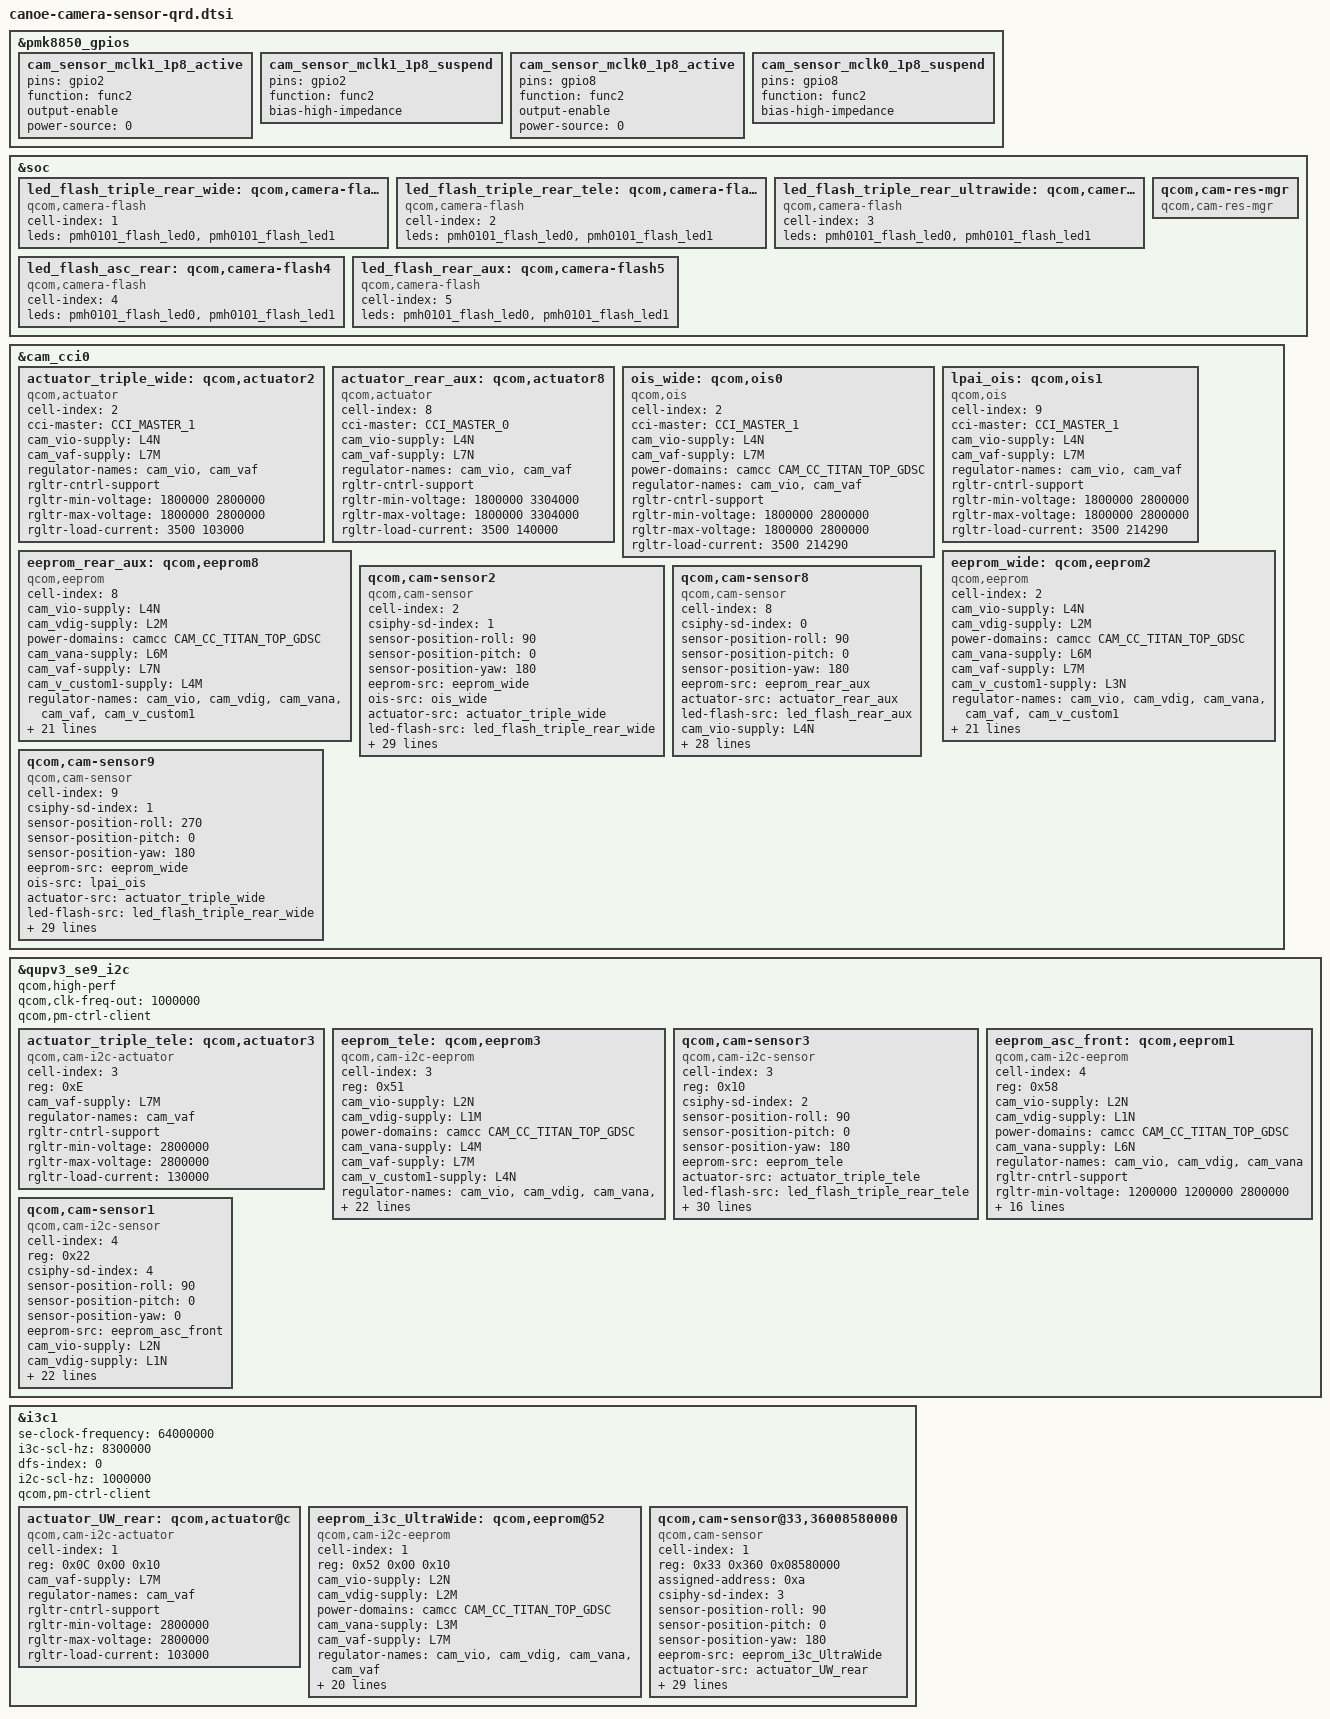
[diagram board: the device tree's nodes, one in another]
// SPDX-License-Identifier: BSD-3-Clause
/*
 * Copyright (c) 2024 Qualcomm Innovation Center, Inc. All rights reserved.
 */

#include <dt-bindings/msm-camera.h>

&pmk8850_gpios {
	cam_sensor_mclk1_1p8_active: cam_sensor_mclk1_1p8_active {
			pins = "gpio2";
			function = "func2";
			output-enable;
			power-source = <0>; /* 1.8 V */
	};

	cam_sensor_mclk1_1p8_suspend: cam_sensor_mclk1_1p8_suspend {
			pins = "gpio2";
			function = "func2";
			bias-high-impedance;
	};

	cam_sensor_mclk0_1p8_active: cam_sensor_mclk0_1p8_active {
			pins = "gpio8";
			function = "func2";
			output-enable;
			power-source = <0>; /* 1.8 V */
	};

	cam_sensor_mclk0_1p8_suspend: cam_sensor_mclk0_1p8_suspend {
			pins = "gpio8";
			function = "func2";
			bias-high-impedance;
	};
};

&soc {
	led_flash_triple_rear_wide: qcom,camera-flash1 {
		cell-index = <1>;
		compatible = "qcom,camera-flash";
		leds = <&pmh0101_flash_led0 &pmh0101_flash_led1>;
		status = "ok";
	};

	led_flash_triple_rear_tele: qcom,camera-flash2 {
		cell-index = <2>;
		compatible = "qcom,camera-flash";
		leds = <&pmh0101_flash_led0 &pmh0101_flash_led1>;
		status = "ok";
	};

	led_flash_triple_rear_ultrawide: qcom,camera-flash3 {
		cell-index = <3>;
		compatible = "qcom,camera-flash";
		leds = <&pmh0101_flash_led0 &pmh0101_flash_led1>;
		status = "ok";
	};

	led_flash_asc_rear: qcom,camera-flash4 {
		cell-index = <4>;
		compatible = "qcom,camera-flash";
		leds = <&pmh0101_flash_led0 &pmh0101_flash_led1>;
		status = "ok";
	};

	led_flash_rear_aux: qcom,camera-flash5 {
		cell-index = <5>;
		compatible = "qcom,camera-flash";
		leds = <&pmh0101_flash_led0 &pmh0101_flash_led1>;
		status = "ok";
	};

	qcom,cam-res-mgr {
		compatible = "qcom,cam-res-mgr";
		status = "ok";
	};
};

&cam_cci0 {

	actuator_triple_wide: qcom,actuator2 {
		cell-index = <2>;
		compatible = "qcom,actuator";
		cci-master = <CCI_MASTER_1>;
		cam_vio-supply = <&L4N>;
		cam_vaf-supply = <&L7M>;
		regulator-names = "cam_vio","cam_vaf";
		rgltr-cntrl-support;
		rgltr-min-voltage = <1800000 2800000>;
		rgltr-max-voltage = <1800000 2800000>;
		rgltr-load-current = <3500 103000>;
		status = "ok";
	};

	actuator_rear_aux: qcom,actuator8 {
		cell-index = <8>;
		compatible = "qcom,actuator";
		cci-master = <CCI_MASTER_0>;
		cam_vio-supply = <&L4N>;
		cam_vaf-supply = <&L7N>;
		regulator-names = "cam_vio","cam_vaf";
		rgltr-cntrl-support;
		rgltr-min-voltage = <1800000 3304000>;
		rgltr-max-voltage = <1800000 3304000>;
		rgltr-load-current = <3500 140000>;
		status = "ok";
	};

	ois_wide: qcom,ois0 {
		cell-index = <2>;
		compatible = "qcom,ois";
		cci-master = <CCI_MASTER_1>;
		cam_vio-supply = <&L4N>;
		cam_vaf-supply = <&L7M>;
		power-domains = <&camcc CAM_CC_TITAN_TOP_GDSC>;
		regulator-names = "cam_vio","cam_vaf";
		rgltr-cntrl-support;
		rgltr-min-voltage = <1800000 2800000>;
		rgltr-max-voltage = <1800000 2800000>;
		rgltr-load-current = <3500 214290>;
		status = "ok";
	};

	lpai_ois: qcom,ois1 {
		cell-index = <9>;
		compatible = "qcom,ois";
		cci-master = <CCI_MASTER_1>;
		cam_vio-supply = <&L4N>;
		cam_vaf-supply = <&L7M>;
		regulator-names = "cam_vio","cam_vaf";
		rgltr-cntrl-support;
		rgltr-min-voltage = <1800000 2800000>;
		rgltr-max-voltage = <1800000 2800000>;
		rgltr-load-current = <3500 214290>;
		status = "ok";
	};

	eeprom_rear_aux: qcom,eeprom8 {
		cell-index = <8>;
		compatible = "qcom,eeprom";
		cam_vio-supply = <&L4N>;
		cam_vdig-supply = <&L2M>;
		power-domains = <&camcc CAM_CC_TITAN_TOP_GDSC>;
		cam_vana-supply = <&L6M>;
		cam_vaf-supply = <&L7N>;
		cam_v_custom1-supply = <&L4M>;
		regulator-names = "cam_vio", "cam_vdig", "cam_vana",
			"cam_vaf", "cam_v_custom1";
		rgltr-cntrl-support;
		rgltr-min-voltage = <1800000 1100000 2800000 3304000 2200000>;
		rgltr-max-voltage = <1800000 1100000 2800000 3304000 2200000>;
		rgltr-load-current = <4280 1050000 114500 140000 127100>;
		gpio-no-mux = <0>;
		pinctrl-names = "cam_default", "cam_suspend";
		pinctrl-0 = <&cam_sensor_mclk0_1p8_active
				 &cam_sensor_1p8_rst0_active>;
		pinctrl-1 = <&cam_sensor_mclk0_1p8_suspend
				 &cam_sensor_1p8_rst0_suspend>;
		gpios = <&pmh0101_gpios 4 0>;
		gpio-reset = <0>;
		gpio-req-tbl-num = <0>;
		gpio-req-tbl-flags = <0>;
		gpio-req-tbl-label = "CAM_RESET0_1P8";
		cci-master = <CCI_MASTER_0>;
		clocks = <&rpmhcc RPMH_DIV_CLK1>;
		clock-names = "cam_clk";
		clock-cntl-level = "nominal";
		clock-rates = <24000000>;
		status = "ok";
	};

	eeprom_wide: qcom,eeprom2 {
		cell-index = <2>;
		compatible = "qcom,eeprom";
		cam_vio-supply = <&L4N>;
		cam_vdig-supply = <&L2M>;
		power-domains = <&camcc CAM_CC_TITAN_TOP_GDSC>;
		cam_vana-supply = <&L6M>;
		cam_vaf-supply = <&L7M>;
		cam_v_custom1-supply = <&L3N>;
		regulator-names = "cam_vio", "cam_vdig", "cam_vana",
			"cam_vaf", "cam_v_custom1";
		rgltr-cntrl-support;
		rgltr-min-voltage = <1800000 1100000 2800000 2800000 1800000>;
		rgltr-max-voltage = <1800000 1100000 2800000 2800000 1800000>;
		rgltr-load-current = <3500 913200 91430 103000 63100>;
		gpio-no-mux = <0>;
		pinctrl-names = "cam_default", "cam_suspend";
		pinctrl-0 = <&cam_sensor_mclk1_1p8_active
				&cam_sensor_active_rst1>;
		pinctrl-1 = <&cam_sensor_mclk1_1p8_suspend
				&cam_sensor_suspend_rst1>;
		gpios = <&tlmm 15 0>;
		gpio-reset = <0>;
		gpio-req-tbl-num = <0>;
		gpio-req-tbl-flags = <0>;
		gpio-req-tbl-label = "CAM_RESET1";
		cci-master = <CCI_MASTER_1>;
		clocks = <&rpmhcc RPMH_DIV_CLK1>;
		clock-names = "cam_clk";
		clock-cntl-level = "nominal";
		clock-rates = <24000000>;
		status = "ok";
	};

	qcom,cam-sensor2 {
		cell-index = <2>;
		compatible = "qcom,cam-sensor";
		csiphy-sd-index = <1>;
		sensor-position-roll = <90>;
		sensor-position-pitch = <0>;
		sensor-position-yaw = <180>;
		eeprom-src = <&eeprom_wide>;
		ois-src = <&ois_wide>;
		actuator-src = <&actuator_triple_wide>;
		led-flash-src = <&led_flash_triple_rear_wide>;
		cam_vio-supply = <&L4N>;
		cam_vdig-supply = <&L2M>;
		power-domains = <&camcc CAM_CC_TITAN_TOP_GDSC>;
		cam_vana-supply = <&L6M>;
		cam_vaf-supply = <&L7M>;
		cam_v_custom1-supply = <&L3N>;
		regulator-names = "cam_vio", "cam_vdig","cam_vana",
			"cam_vaf", "cam_v_custom1";
		rgltr-cntrl-support;
		rgltr-min-voltage = <1800000 1100000 2800000 2800000 1800000>;
		rgltr-max-voltage = <1800000 1100000 2800000 2800000 1800000>;
		rgltr-load-current = <3500 913200 91430 103000 63100>;
		gpio-no-mux = <0>;
		pinctrl-names = "cam_default", "cam_suspend";
		pinctrl-0 = <&cam_sensor_mclk1_1p8_active
				 &cam_sensor_active_rst1>;
		pinctrl-1 = <&cam_sensor_mclk1_1p8_suspend
				 &cam_sensor_suspend_rst1>;
		gpios = <&tlmm 15 0>;
		gpio-reset = <0>;
		gpio-req-tbl-num = <0>;
		gpio-req-tbl-flags = <0>;
		gpio-req-tbl-label = "CAM_RESET1";
		cci-master = <CCI_MASTER_1>;
		clocks = <&rpmhcc RPMH_DIV_CLK1>;
		clock-names = "cam_clk";
		clock-cntl-level = "nominal";
		clock-rates = <24000000>;
		status = "ok";
	};

	qcom,cam-sensor8 {
		cell-index = <8>;
		compatible = "qcom,cam-sensor";
		csiphy-sd-index = <0>;
		sensor-position-roll = <90>;
		sensor-position-pitch = <0>;
		sensor-position-yaw = <180>;
		eeprom-src = <&eeprom_rear_aux>;
		actuator-src = <&actuator_rear_aux>;
		led-flash-src = <&led_flash_rear_aux>;
		cam_vio-supply = <&L4N>;
		cam_vdig-supply = <&L2M>;
		power-domains = <&camcc CAM_CC_TITAN_TOP_GDSC>;
		cam_vana-supply = <&L6M>;
		cam_vaf-supply = <&L7N>;
		cam_v_custom1-supply = <&L4M>;
		regulator-names = "cam_vio", "cam_vdig", "cam_vana",
			"cam_vaf", "cam_v_custom1";
		rgltr-cntrl-support;
		rgltr-min-voltage = <1800000 1100000 2800000 3304000 2200000>;
		rgltr-max-voltage = <1800000 1100000 2800000 3304000 2200000>;
		rgltr-load-current = <4280 1050000 114500 140000 127100>;
		gpio-no-mux = <0>;
		pinctrl-names = "cam_default", "cam_suspend";
		pinctrl-0 = <&cam_sensor_mclk0_1p8_active
				 &cam_sensor_1p8_rst0_active>;
		pinctrl-1 = <&cam_sensor_mclk0_1p8_suspend
				 &cam_sensor_1p8_rst0_suspend>;
		gpios = <&pmh0101_gpios 4 0>;
		gpio-reset = <0>;
		gpio-req-tbl-num = <0>;
		gpio-req-tbl-flags = <0>;
		gpio-req-tbl-label = "CAM_RESET0_1P8";
		cci-master = <CCI_MASTER_0>;
		clocks = <&rpmhcc RPMH_DIV_CLK1>;
		clock-names = "cam_clk";
		clock-cntl-level = "nominal";
		clock-rates = <24000000>;
		status = "ok";
	};

	qcom,cam-sensor9 {
		cell-index = <9>;
		compatible = "qcom,cam-sensor";
		csiphy-sd-index = <1>;
		sensor-position-roll = <270>;
		sensor-position-pitch = <0>;
		sensor-position-yaw = <180>;
		eeprom-src = <&eeprom_wide>;
		ois-src = <&lpai_ois>;
		actuator-src = <&actuator_triple_wide>;
		led-flash-src = <&led_flash_triple_rear_wide>;
		cam_vio-supply = <&L4N>;
		cam_vdig-supply = <&L2M>;
		power-domains = <&camcc CAM_CC_TITAN_TOP_GDSC>;
		cam_vana-supply = <&L6M>;
		cam_vaf-supply = <&L7M>;
		cam_v_custom1-supply = <&L3N>;
		regulator-names = "cam_vio", "cam_vdig", "cam_vana",
			"cam_vaf", "cam_v_custom1";
		rgltr-cntrl-support;
		rgltr-min-voltage = <1800000 1100000 2800000 2800000 1800000>;
		rgltr-max-voltage = <1800000 1100000 2800000 2800000 1800000>;
		rgltr-load-current = <3500 913200 91430 103000 63100>;
		gpio-no-mux = <0>;
		pinctrl-names = "cam_default", "cam_suspend";
		pinctrl-0 = <&cam_sensor_mclk1_1p8_active
				 &cam_sensor_1p8_rst1_active>;
		pinctrl-1 = <&cam_sensor_mclk1_1p8_suspend
				 &cam_sensor_1p8_rst1_suspend>;
		gpios = <&pmh0110_i_gpios 12 0>;
		gpio-reset = <0>;
		gpio-req-tbl-num = <0>;
		gpio-req-tbl-flags = <0>;
		gpio-req-tbl-label = "CAM_RESET1_1P8";
		cci-master = <CCI_MASTER_1>;
		clocks = <&rpmhcc RPMH_DIV_CLK1>;
		clock-names = "cam_clk";
		clock-cntl-level = "nominal";
		clock-rates = <24000000>;
		status = "ok";
	};
};

&qupv3_se9_i2c {
	status = "ok";
	qcom,high-perf;
	qcom,clk-freq-out = <1000000>;
	qcom,pm-ctrl-client;

	actuator_triple_tele: qcom,actuator3 {
		cell-index = <3>;
		reg = <0xE>;
		compatible = "qcom,cam-i2c-actuator";
		cam_vaf-supply = <&L7M>;
		regulator-names = "cam_vaf";
		rgltr-cntrl-support;
		rgltr-min-voltage = <2800000>;
		rgltr-max-voltage = <2800000>;
		rgltr-load-current = <130000>;
		status = "ok";
	};

	eeprom_tele: qcom,eeprom3 {
		cell-index = <3>;
		reg = <0x51>;
		compatible = "qcom,cam-i2c-eeprom";
		cam_vio-supply = <&L2N>;
		cam_vdig-supply = <&L1M>;
		power-domains = <&camcc CAM_CC_TITAN_TOP_GDSC>;
		cam_vana-supply = <&L4M>;
		cam_vaf-supply = <&L7M>;
		cam_v_custom1-supply = <&L4N>;
		regulator-names = "cam_vio", "cam_vdig",
			"cam_vana", "cam_vaf", "cam_v_custom1";
		rgltr-cntrl-support;
		rgltr-min-voltage = <1200000 1000000 2200000 2800000 1800000>;
		rgltr-max-voltage = <1200000 1000000 2200000 2800000 1800000>;
		rgltr-load-current = <6000 274050 86550 130000 2570>;
		gpio-no-mux = <0>;
		pinctrl-names = "cam_default", "cam_suspend";
		pinctrl-0 = <&cam_sensor_mclk2_active
				 &cam_sensor_active_rst2>;
		pinctrl-1 = <&cam_sensor_mclk2_suspend
				 &cam_sensor_suspend_rst2>;
		gpios = <&tlmm 91 0>,
			<&tlmm 3 0>;
		gpio-reset = <1>;
		gpio-req-tbl-num = <0 1>;
		gpio-req-tbl-flags = <1 0>;
		gpio-req-tbl-label = "CAMIF_MCLK2",
					"CAM_RESET2";
		clocks = <&cambistmclkcc CAM_BIST_MCLK_CC_MCLK2_CLK>;
		clock-names = "cam_clk";
		clock-cntl-level = "nominal";
		clock-rates = <24000000>;
		status = "ok";
	};

	qcom,cam-sensor3 {
		cell-index = <3>;
		reg = <0x10>;
		compatible = "qcom,cam-i2c-sensor";
		csiphy-sd-index = <2>;
		sensor-position-roll = <90>;
		sensor-position-pitch = <0>;
		sensor-position-yaw = <180>;
		eeprom-src = <&eeprom_tele>;
		actuator-src = <&actuator_triple_tele>;
		led-flash-src = <&led_flash_triple_rear_tele>;
		cam_vio-supply = <&L2N>;
		cam_vdig-supply = <&L1M>;
		power-domains = <&camcc CAM_CC_TITAN_TOP_GDSC>;
		cam_vana-supply = <&L4M>;
		cam_vaf-supply = <&L7M>;
		cam_v_custom1-supply = <&L4N>;
		regulator-names = "cam_vio", "cam_vdig",
			"cam_vana", "cam_vaf", "cam_v_custom1";
		rgltr-cntrl-support;
		aon-camera-id = <AON_CAM2>;
		rgltr-min-voltage = <1200000 1000000 2200000 2800000 1800000>;
		rgltr-max-voltage = <1200000 1000000 2200000 2800000 1800000>;
		rgltr-load-current = <6000 274050 86550 130000 2570>;
		gpio-no-mux = <0>;
		pinctrl-names = "cam_default", "cam_suspend";
		pinctrl-0 = <&cam_sensor_mclk2_active
				 &cam_sensor_active_rst2>;
		pinctrl-1 = <&cam_sensor_mclk2_suspend
				 &cam_sensor_suspend_rst2>;
		gpios = <&tlmm 91 0>,
			<&tlmm 3 0>;
		gpio-reset = <1>;
		gpio-req-tbl-num = <0 1>;
		gpio-req-tbl-flags = <1 0>;
		gpio-req-tbl-label = "CAMIF_MCLK2",
					"CAM_RESET2";
		clocks = <&cambistmclkcc CAM_BIST_MCLK_CC_MCLK2_CLK>;
		clock-names = "cam_clk";
		clock-cntl-level = "nominal";
		clock-rates = <24000000>;
		status = "ok";
	};

	eeprom_asc_front: qcom,eeprom1 {
		cell-index = <4>;
		reg = <0x58>;
		compatible = "qcom,cam-i2c-eeprom";
		cam_vio-supply = <&L2N>;
		cam_vdig-supply = <&L1N>;
		power-domains = <&camcc CAM_CC_TITAN_TOP_GDSC>;
		cam_vana-supply = <&L6N>;
		regulator-names = "cam_vio", "cam_vdig", "cam_vana";
		rgltr-cntrl-support;
		rgltr-min-voltage = <1200000 1200000 2800000>;
		rgltr-max-voltage = <1200000 1200000 2800000>;
		rgltr-load-current = <3000 283000 50000>;
		gpio-no-mux = <0>;
		pinctrl-names = "cam_default", "cam_suspend";
		pinctrl-0 = <&cam_sensor_mclk4_active
				 &cam_sensor_active_rst4>;
		pinctrl-1 = <&cam_sensor_mclk4_suspend
				 &cam_sensor_suspend_rst4>;
		gpios = <&tlmm 93 0>,
			<&tlmm 7 0>;
		gpio-reset = <1>;
		gpio-req-tbl-num = <0 1>;
		gpio-req-tbl-flags = <1 0>;
		gpio-req-tbl-label = "CAMIF_MCLK4",
					"CAM_RESET4";
		clocks = <&cambistmclkcc CAM_BIST_MCLK_CC_MCLK4_CLK>;
		clock-names = "cam_clk";
		clock-cntl-level = "nominal";
		clock-rates = <24000000>;
		status = "ok";
	};

	 qcom,cam-sensor1 {
		cell-index = <4>;
		reg = <0x22>;
		compatible = "qcom,cam-i2c-sensor";
		csiphy-sd-index = <4>;
		sensor-position-roll = <90>;
		sensor-position-pitch = <0>;
		sensor-position-yaw = <0>;
		eeprom-src = <&eeprom_asc_front>;
		cam_vio-supply = <&L2N>;
		cam_vdig-supply = <&L1N>;
		power-domains = <&camcc CAM_CC_TITAN_TOP_GDSC>;
		cam_vana-supply = <&L6N>;
		regulator-names = "cam_vio", "cam_vdig", "cam_vana";
		rgltr-cntrl-support;
		aon-camera-id = <AON_CAM1>;
		rgltr-min-voltage = <1200000 1200000 2800000>;
		rgltr-max-voltage = <1200000 1200000 2800000>;
		rgltr-load-current = <3000 283000 50000>;
		gpio-no-mux = <0>;
		pinctrl-names = "cam_default", "cam_suspend";
		pinctrl-0 = <&cam_sensor_mclk4_active
				 &cam_sensor_active_rst4>;
		pinctrl-1 = <&cam_sensor_mclk4_suspend
				 &cam_sensor_suspend_rst4>;
		gpios = <&tlmm 93 0>,
			<&tlmm 7 0>;
		gpio-reset = <1>;
		gpio-req-tbl-num = <0 1>;
		gpio-req-tbl-flags = <1 0>;
		gpio-req-tbl-label = "CAMIF_MCLK4",
					"CAM_RESET4";
		clocks = <&cambistmclkcc CAM_BIST_MCLK_CC_MCLK4_CLK>;
		clock-names = "cam_clk";
		clock-cntl-level = "nominal";
		clock-rates = <24000000>;
		status = "ok";
	};
};

&i3c1 {
	se-clock-frequency = <64000000>;
	i3c-scl-hz = <8300000>;
	dfs-index = <0>;
	i2c-scl-hz = <1000000>;
	qcom,pm-ctrl-client;
	status = "ok";

	actuator_UW_rear: qcom,actuator@c {
		cell-index = <1>;
		reg = <0x0C 0x00 0x10>;
		compatible = "qcom,cam-i2c-actuator";
		cam_vaf-supply = <&L7M>;
		regulator-names = "cam_vaf";
		rgltr-cntrl-support;
		rgltr-min-voltage = <2800000>;
		rgltr-max-voltage = <2800000>;
		rgltr-load-current = <103000>;
		status = "ok";
	};

	eeprom_i3c_UltraWide: qcom,eeprom@52 {
		cell-index = <1>;
		reg = <0x52 0x00 0x10>;
		compatible = "qcom,cam-i2c-eeprom";
		cam_vio-supply = <&L2N>;
		cam_vdig-supply = <&L2M>;
		power-domains = <&camcc CAM_CC_TITAN_TOP_GDSC>;
		cam_vana-supply = <&L3M>;
		cam_vaf-supply = <&L7M>;
		regulator-names = "cam_vio", "cam_vdig", "cam_vana",
			"cam_vaf";
		rgltr-cntrl-support;
		rgltr-min-voltage = <1200000 1100000 2800000 2800000>;
		rgltr-max-voltage = <1200000 1100000 2800000 2800000>;
		rgltr-load-current = <3500 522730 107140 103000>;
		gpio-no-mux = <0>;
		pinctrl-names = "cam_default", "cam_suspend";
		pinctrl-0 = <&cam_sensor_mclk3_active
				&cam_sensor_active_rst3>;
		pinctrl-1 = <&cam_sensor_mclk3_suspend
				&cam_sensor_suspend_rst3>;
		gpios = <&tlmm 92 0>,
			<&tlmm 105 0>;
		gpio-reset = <1>;
		gpio-req-tbl-num = <0 1>;
		gpio-req-tbl-flags = <1 0>;
		gpio-req-tbl-label = "CAMIF_MCLK3",
					"CAM_RESET3";
		clocks = <&cambistmclkcc CAM_BIST_MCLK_CC_MCLK3_CLK>;
		clock-names = "cam_clk";
		clock-cntl-level = "nominal";
		clock-rates = <24000000>;
		status = "ok";
	};

	qcom,cam-sensor@33,36008580000 {
		cell-index = <1>;
		reg = <0x33 0x360 0x08580000>;
		assigned-address = <0xa>;
		compatible = "qcom,cam-sensor";
		csiphy-sd-index = <3>;
		sensor-position-roll = <90>;
		sensor-position-pitch = <0>;
		sensor-position-yaw = <180>;
		eeprom-src = <&eeprom_i3c_UltraWide>;
		actuator-src = <&actuator_UW_rear>;
		led-flash-src = <&led_flash_triple_rear_ultrawide>;
		cam_vio-supply = <&L2N>;
		cam_vdig-supply = <&L2M>;
		power-domains = <&camcc CAM_CC_TITAN_TOP_GDSC>;
		cam_vana-supply = <&L3M>;
		cam_vaf-supply = <&L7M>;
		regulator-names = "cam_vio", "cam_vdig", "cam_vana",
			"cam_vaf";
		rgltr-cntrl-support;
		i3c-target;
		rgltr-min-voltage = <1200000 1100000 2800000 2800000>;
		rgltr-max-voltage = <1200000 1100000 2800000 2800000>;
		rgltr-load-current = <3500 522730 107140 103000>;
		gpio-no-mux = <0>;
		pinctrl-names = "cam_default", "cam_suspend";
		pinctrl-0 = <&cam_sensor_mclk3_active
				&cam_sensor_active_rst3>;
		pinctrl-1 = <&cam_sensor_mclk3_suspend
				&cam_sensor_suspend_rst3>;
		gpios = <&tlmm 92 0>,
			<&tlmm 105 0>;
		gpio-reset = <1>;
		gpio-req-tbl-num = <0 1>;
		gpio-req-tbl-flags = <1 0>;
		gpio-req-tbl-label = "CAMIF_MCLK3",
					"CAM_RESET3";
		clocks = <&cambistmclkcc CAM_BIST_MCLK_CC_MCLK3_CLK>;
		clock-names = "cam_clk";
		clock-cntl-level = "nominal";
		clock-rates = <24000000>;
		status = "ok";
	};
};
